# TC35680 register map
Vendor: Toshiba Electronic Devices and Storage Corporation; File version: 0.1
CPU: CM0 r0p0, little endian, no MPU, no FPU, 4 interrupt priority bits
Registers are 32-bit, read-write, no defined reset value unless marked. A register's access mark holds for its fields unless they carry their own. Offsets are from the block's base; [hi:lo] are bit positions; {n}, {i} and the like mark numbered series.

## PWM — Pulse Width Modulation
Base 0x4004A100
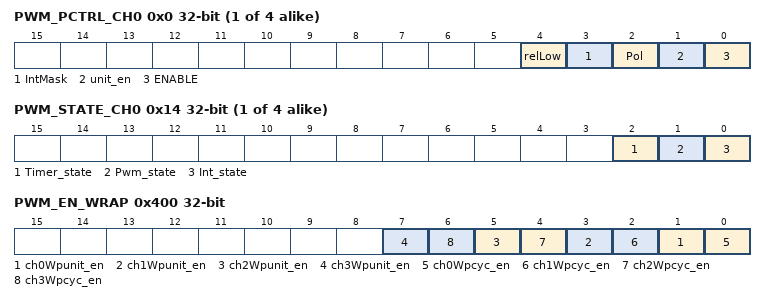
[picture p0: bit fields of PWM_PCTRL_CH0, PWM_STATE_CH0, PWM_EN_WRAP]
{0x0+0x100*i} PWM_PCTRL_CH{i} (i=0..3) — PWM CH{i} enable control
  [4] relLow — Keep the output when entering LowPowerMode
  [3] IntMask — PWM interrupt mask (R/W). 0: Interrupt output enabled. 1: Interrupt disabled (default)
  [2] Pol — PWM output polarity control (R/W). 0: Polarity inversion OFF (default). 1: Polarity inversion ON
  [1] unit_en — 1-s timer enable (R/W). 0: Timer OFF (default). 1: Timer ON Please set this off before unit_starvalue is to be changed. When this is off, rhythm settings has no effect.
  [0] ENABLE — PWM channel enable (R/W). 0: Stop (default). 1: Start. Please set cycle and duty before this is set to start.
{0x4+0x100*i} PWM_PATTERN_CH{i} (i=0..3) — PWM CH{i} output mask set
  [19:0] Rhythm_Pat — PWM is output during the time this defines. 1 bit corresponds to 50 ms. 0: Output mask ON (No PWM output). 1: Output mask OFF (PWM output). This has no effect when 1-s timer is OFF.
{0x8+0x100*i} PWM_CYCLE_CH{i} (i=0..3) — PWM CH{i} cycle set
  [11:0] Cycle — Cycle count register determines the PWM output period. 0 to 4095 (0x000 to 0xFFF)
0x0C PWM_DUTY_CH0 — PWM CH0 duty set
  [11:0] Duty — Determines the duty ratio. 0 to 4095 (0x000 to 0xFFF) duty ratio = (this value)/(cycle + 1)
{0x10+0x100*i} PWM_UNIT_CH{i} (i=0..3) — PWM CH{i} rhythm counter period set
  [19:0] Unit_startvalue — Counter value setting to count 50 ms. 0x0665 for 32.768 kHz (default). 0x9EB0F for 13 MHz. Before to change this value, please make sure that PCTRL[1] unit_en = 0, STATE[2] Timer_state = 1, Pwm_state = 1.
{0x14+0x100*i} PWM_STATE_CH{i} (i=0..3) — PWM CH{i} status
  [2] Timer_state — 1-s timer status. 0: ON. 1: Idle
  [1] Pwm_state — Cycle counter status. 0: ON. 1: Idle
  [0] Int_state — INT status. 0: Not interrupted. 1: Interrupted. This is cleared when INTClr bit 0 is set to 1.
{0x18+0x100*i} PWM_INTCLR_CH{i} (i=0..3) — PWM CH{i} interrupt clear
  [0] IntClr — PWM interrupt clear register (initial 0, W). Writeing 1 to this register clears the interrupt status.
{0xC+0x100*i} PWM_DUTY_CH{i} (i=1..3) — PWM CH{i} duty set
  [11:0] Duty — Determines the duty ratio. 0 to 4095 (0x000 to 0xFFF). duty ratio = (this value)/(cycle + 1)
0x400 PWM_EN_WRAP — PWM wave phase control
  [2n+1] ch{n}Wpunit_en (n=0..3) — PWM{n} unit_en
  [2n] ch{n}Wpcyc_en (n=0..3) — PWM{n} enable

## TimerBCG — Timer (BCTimer, GTimer)
Base 0x4004D000
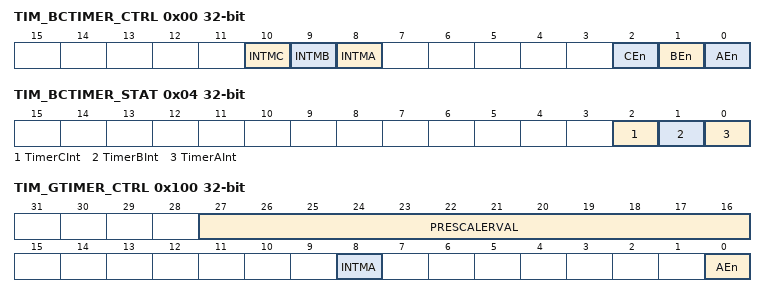
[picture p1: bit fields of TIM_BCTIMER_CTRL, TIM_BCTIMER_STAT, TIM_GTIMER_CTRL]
0x00 TIM_BCTIMER_CTRL — Bit Clock Timer Control
  [10] INTMC — Timer C Interrupt mask. 0: the interrupt is not masked. 1: the interutpt is masked
  [9] INTMB — Timer B Interrupt mask. 0: the interrupt is not masked. 1: the interutpt is masked
  [8] INTMA — Timer A Interrupt mask. 0: the interrupt is not masked. 1: the interutpt is masked
  [2] CEn — Enable autoreload feature for timer C. 0: Stop when Timer C gets 0. 1: Reload the initial value when Timer C gets 0.
  [1] BEn — Enable autoreload feature for timer B. 0: Stop when Timer B gets 0. 1: Reload the initial value when Timer B gets 0.
  [0] AEn — Enable autoreload feature for timer A. 0: Stop when Timer A gets 0. 1: Reload the initial value when Timer A gets 0.
0x04 TIM_BCTIMER_STAT — Bit Clock Timer Status
  [2] TimerCInt — Interrupt from Timer C. 0: No interrupt from Timer C. 1: Interrupt from Timer C exist.
  [1] TimerBInt — Interrupt from Timer B. 0: No interrupt from Timer B. 1: Interrupt from Timer B exist.
  [0] TimerAInt — Interrupt from Timer A. 0: No interrupt from Timer A. 1: Interrupt from Timer A exist.
0x08 TIM_BCTIMER_A — Bit Clock Timer A control
  [15:0] TimA — Start Value Timer A. Set the initial value of Timer A.
0x0C TIM_BCTIMER_B — Bit Clock Timer B control
  [15:0] TimB — Start Value Timer B. Set the initial value of Timer B.
0x10 TIM_BCTIMER_C — Bit Clock Timer C control
  [15:0] TimC — Start Value Timer C. Set the initial value of Timer C.
0x14 TIM_BCTIMER_A_RD — Bit Clock Timer A read
  [15:0] TimARd — Current Value of Timer A
0x18 TIM_BCTIMER_B_RD — Bit Clock Timer B read
  [15:0] TimBRd — Current Value of Timer B
0x1C TIM_BCTIMER_C_RD — Bit Clock Timer C read
  [15:0] TimCRd — Current Value of Timer C
0x100 TIM_GTIMER_CTRL — Timer Control
  [27:16] PRESCALERVAL — Settings for frequency divider of TimerSCLK to generate timer clock. 0x000 : No divide. 0x001 : 1/2. 0x002 : 1/3. ........ 0xfff : 1/4096
  [8] INTMA — Timer A Interrupt mask. 0: the interrupt is not masked. 1: the interutpt is masked
  [0] AEn — Enable auto reload feature for Timer A
0x104 TIM_GTIMER_STAT — Timer Status
  [0] TimerAInt — Interrutp bit from Timer A. 0: No interrupt from Timer A. 1: Interrupt from Timer A exist.
0x108 TIM_GTIMER_A — Timer Initial Value
  [15:0] TimA — Start Value of TimerA.
0x114 TIM_GTIMER_A_RD — Timer Value read
  [15:0] TimerARd — Current Value of Timer A.
